# ATSAMD51J19A device description
Architecture: CORTEX-M4; Family: SAMD; Series: SAMD51
Registers are 32-bit, read-write, reset 0x0 unless marked. A register's access mark holds for its fields unless they carry their own. Offsets are from the block's base; [hi:lo] are bit positions; {n}, {i} and the like mark numbered series; 'fields as' and 'values as' point back to an identical list.

## Event generators
1 OSCCTRL_XOSC_FAIL_0, 2 OSCCTRL_XOSC_FAIL_1, 3 OSC32KCTRL_XOSC32K_FAIL, {n+4} RTC_PER_{n} (n=0..7), {n+12} RTC_CMP_{n} (n=0..3), 16 RTC_TAMPER, 17 RTC_OVF, {n+18} EIC_EXTINT_{n} (n=0..15), {n+34} DMAC_CH_{n} (n=0..3), 38 PAC_ACCERR, 41 TCC0_OVF, 42 TCC0_TRG, 43 TCC0_CNT, {n+44} TCC0_MC_{n} (n=0..5), 50 TCC1_OVF, 51 TCC1_TRG, 52 TCC1_CNT, {n+53} TCC1_MC_{n} (n=0..3), 57 TCC2_OVF, 58 TCC2_TRG, 59 TCC2_CNT, {n+60} TCC2_MC_{n} (n=0..2), 63 TCC3_OVF, 64 TCC3_TRG, 65 TCC3_CNT, 66 TCC3_MC_0, 67 TCC3_MC_1, 68 TCC4_OVF, 69 TCC4_TRG, 70 TCC4_CNT, 71 TCC4_MC_0, 72 TCC4_MC_1, {3n+73} TC{n}_OVF (n=0..5), {3n+74} TC{n}_MC_0 (n=0..5), {3n+75} TC{n}_MC_1 (n=0..5), 97 PDEC_OVF, 98 PDEC_ERR, 99 PDEC_DIR, 100 PDEC_VLC, 101 PDEC_MC_0, 102 PDEC_MC_1, 103 ADC0_RESRDY, 104 ADC0_WINMON, 105 ADC1_RESRDY, 106 ADC1_WINMON, 107 AC_COMP_0, 108 AC_COMP_1, 109 AC_WIN_0, 110 DAC_EMPTY_0, 111 DAC_EMPTY_1, 112 DAC_RESRDY_0, 113 DAC_RESRDY_1, 115 TRNG_READY, {n+116} CCL_LUTOUT_{n} (n=0..3)

## Event users
0 RTC_TAMPER, {n+1} PORT_EV_{n} (n=0..3), {n+5} DMAC_CH_{n} (n=0..7), 14 CM4_TRACE_START, 15 CM4_TRACE_STOP, 16 CM4_TRACE_TRIG, 17 TCC0_EV_0, 18 TCC0_EV_1, {n+19} TCC0_MC_{n} (n=0..5), 25 TCC1_EV_0, 26 TCC1_EV_1, {n+27} TCC1_MC_{n} (n=0..3), 31 TCC2_EV_0, 32 TCC2_EV_1, {n+33} TCC2_MC_{n} (n=0..2), 36 TCC3_EV_0, 37 TCC3_EV_1, 38 TCC3_MC_0, 39 TCC3_MC_1, 40 TCC4_EV_0, 41 TCC4_EV_1, 42 TCC4_MC_0, 43 TCC4_MC_1, {n+44} TC{n}_EVU (n=0..5), {n+52} PDEC_EVU_{n} (n=0..2), 55 ADC0_START, 56 ADC0_SYNC, 57 ADC1_START, 58 ADC1_SYNC, 59 AC_SOC_0, 60 AC_SOC_1, 61 DAC_START_0, 62 DAC_START_1, {n+63} CCL_LUTIN_{n} (n=0..3)

## Properties
SIGNATURES: DSU_DID=0x60060305

## Pinouts (pin number, pad)
SAMD51JU: A1 PA25, A2 PB22, A3 PB23, A4 VDDCORE, A5 VSW, A6 PB30, A7 PB00, A8 PB02, B1 PA24, B2 GNDIO, B3 PA27, B4 RESET_N, B5 VDDIO, B6 PB31, B7 PB01, B8 PA00, C1 PA22, C2 PA23, C3 VDDIO, C4 GNDIO, C5 PA30, C6 PB03, C7 PA02, C8 PA01, D1 PB17, D2 PA20, D3 PA21, D4 PB16, D5 PA31, D6 PA03, D7 PB04, D8 PB05, E1 PA18, E2 PA19, E3 VDDIO, E4 VDDIOB, E5 GNDANA, E6 PB07, E7 PB06, E8 VDDANA, F1 PA17, F2 PA12, F3 GNDIO, F4 GNDIO, F5 PB08, F6 PA05, F7 PA04, F8 PB09, G1 PA16, G2 PA13, G3 PB14, G4 PB11, G5 PA11, G6 PA09, G7 PA06, G8 PA07, H1 PA14, H2 PA15, H3 PB15, H4 PB13, H5 PB12, H6 PB10, H7 PA10, H8 PA08
SAMD51J: 1 PA00, 2 PA01, 3 PA02, 4 PA03, 5 PB04, 6 PB05, 7 GNDANA, 8 VDDANA, 9 PB06, 10 PB07, 11 PB08, 12 PB09, 13 PA04, 14 PA05, 15 PA06, 16 PA07, 17 PA08, 18 PA09, 19 PA10, 20 PA11, 21 VDDIOB, 22 GND, 23 PB10, 24 PB11, 25 PB12, 26 PB13, 27 PB14, 28 PB15, 29 PA12, 30 PA13, 31 PA14, 32 PA15, 33 GND, 34 VDDIO, 35 PA16, 36 PA17, 37 PA18, 38 PA19, 39 PB16, 40 PB17, 41 PA20, 42 PA21, 43 PA22, 44 PA23, 45 PA24, 46 PA25, 47 GND, 48 VDDIO, 49 PB22, 50 PB23, 51 PA27, 52 RESET_N, 53 VDDCORE, 54 GND, 55 VSW, 56 VDDIO, 57 PA30, 58 PA31, 59 PB30, 60 PB31, 61 PB00, 62 PB01, 63 PB02, 64 PB03

## AC — Analog Comparators
Instances: AC 0x42002000
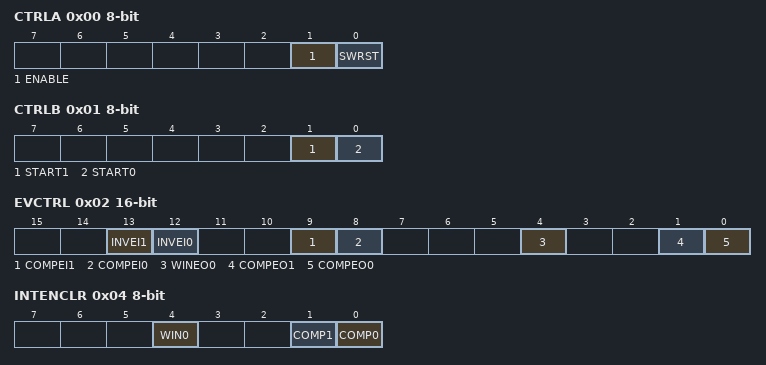
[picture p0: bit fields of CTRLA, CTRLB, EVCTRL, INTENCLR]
0x00 CTRLA 8-bit (WSYNC) — Control A
  [1] ENABLE
  [0] SWRST — Software Reset
0x01 CTRLB 8-bit wo — Control B
  [1] START1 — Comparator 1 Start Comparison
  [0] START0 — Comparator 0 Start Comparison
0x02 EVCTRL 16-bit — Event Control
  [13] INVEI1 — Comparator 1 Input Event Invert Enable
  [12] INVEI0 — Comparator 0 Input Event Invert Enable
  [9] COMPEI1 — Comparator 1 Event Input Enable
  [8] COMPEI0 — Comparator 0 Event Input Enable
  [4] WINEO0 — Window 0 Event Output Enable
  [1] COMPEO1 — Comparator 1 Event Output Enable
  [0] COMPEO0 — Comparator 0 Event Output Enable
0x04 INTENCLR 8-bit (atomic clear) — Interrupt Enable Clear
  [4] WIN0 — Window 0 Interrupt Enable
  [1] COMP1 — Comparator 1 Interrupt Enable
  [0] COMP0 — Comparator 0 Interrupt Enable
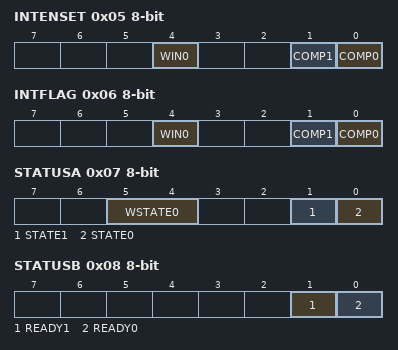
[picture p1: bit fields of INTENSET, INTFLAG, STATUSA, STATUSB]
0x05 INTENSET 8-bit (atomic set) — Interrupt Enable Set
  fields as INTENCLR
0x06 INTFLAG 8-bit (atomic clear) — Interrupt Flag Status and Clear
  [4] WIN0 — Window 0
  [1] COMP1 — Comparator 1
  [0] COMP0 — Comparator 0
0x07 STATUSA 8-bit ro
  [5:4] WSTATE0 — Window 0 Current State
    0=ABOVE (Signal is above window); 1=INSIDE (Signal is inside window); 2=BELOW (Signal is below window)
  [1] STATE1 — Comparator 1 Current State
  [0] STATE0 — Comparator 0 Current State
0x08 STATUSB 8-bit ro
  [1] READY1 — Comparator 1 Ready
  [0] READY0 — Comparator 0 Ready
0x09 DBGCTRL 8-bit — Debug Control
  [0] DBGRUN — Debug Run
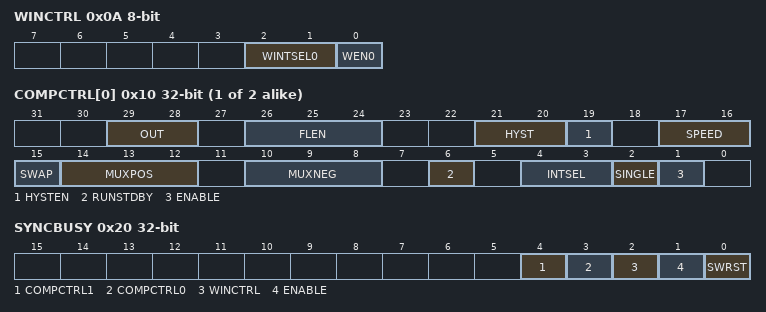
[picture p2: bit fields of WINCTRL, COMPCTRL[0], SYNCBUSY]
0x0A WINCTRL 8-bit (WSYNC) — Window Control
  [2:1] WINTSEL0 — Window 0 Interrupt Selection
    0=ABOVE (Interrupt on signal above window); 1=INSIDE (Interrupt on signal inside window); 2=BELOW (Interrupt on signal below window); 3=OUTSIDE (Interrupt on signal outside window)
  [0] WEN0 — Window 0 Mode Enable
{0xC+i} SCALER[{i}] (i=0..1) 8-bit — Scaler n
  [5:0] VALUE — Scaler Value
{0x10+4i} COMPCTRL[{i}] (i=0..1) — Comparator Control n
  [29:28] OUT — Output
    0=OFF (The output of COMPn is not routed to the COMPn I/O port); 1=ASYNC (The asynchronous output of COMPn is routed to the COMPn I/O port); 2=SYNC (The synchronous output (including filtering) of COMPn is routed to the COMPn I/O port)
  [26:24] FLEN — Filter Length
    0=OFF (No filtering); 1=MAJ3 (3-bit majority function (2 of 3)); 2=MAJ5 (5-bit majority function (3 of 5))
  [21:20] HYST — Hysteresis Level
    0=25mV; 1=50mV; 2=75mV; 3=100mV
  [19] HYSTEN — Hysteresis Enable
  [17:16] SPEED — Speed Selection
    3=HIGH (High speed)
  [15] SWAP — Swap Inputs and Invert
  [14:12] MUXPOS — Positive Input Mux Selection
    {v}=PIN{v} (I/O pin {v}) (v=0..3); 4=VSCALE (VDD Scaler)
  [10:8] MUXNEG — Negative Input Mux Selection
    {v}=PIN{v} (I/O pin {v}) (v=0..3); 4=GND (Ground); 5=VSCALE (VDD scaler); 6=BANDGAP (Internal bandgap voltage); 7=DAC (DAC output)
  [6] RUNSTDBY — Run in Standby
  [4:3] INTSEL — Interrupt Selection
    0=TOGGLE (Interrupt on comparator output toggle); 1=RISING (Interrupt on comparator output rising); 2=FALLING (Interrupt on comparator output falling); 3=EOC (Interrupt on end of comparison (single-shot mode only))
  [2] SINGLE — Single-Shot Mode
  [1] ENABLE
0x20 SYNCBUSY ro — Synchronization Busy
  [4] COMPCTRL1 — COMPCTRL 1 Synchronization Busy
  [3] COMPCTRL0 — COMPCTRL 0 Synchronization Busy
  [2] WINCTRL — WINCTRL Synchronization Busy
  [1] ENABLE — Enable Synchronization Busy
  [0] SWRST — Software Reset Synchronization Busy
0x24 CALIB 16-bit reset 0x101 — Calibration
  [1:0] BIAS0 — COMP0/1 Bias Scaling

## Notices in the file
Copyright (c) 2021 Microchip Technology Inc.
SPDX-License-Identifier: Apache-2.0
Licensed under the Apache License, Version 2.0 (the "License");
you may not use this file except in compliance with the License.
You may obtain a copy of the License at
http://www.apache.org/licenses/LICENSE-2.0
Unless required by applicable law or agreed to in writing, software
distributed under the License is distributed on an "AS IS" BASIS,
WITHOUT WARRANTIES OR CONDITIONS OF ANY KIND, either express or implied.
See the License for the specific language governing permissions and
limitations under the License.
